# ATmega8535 device description
Architecture: AVR8; Family: megaAVR
Registers are 8-bit, access not given, no defined reset value unless marked. A register's access mark holds for its fields unless they carry their own. Offsets are from the block's base; [hi:lo] are bit positions.

## AC — Analog Comparator
Instances: AC 0x00
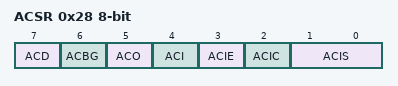
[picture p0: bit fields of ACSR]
0x28 ACSR — Analog Comparator Control And Status Register
  [7] ACD — Analog Comparator Disable
  [6] ACBG — Analog Comparator Bandgap Select
  [5] ACO — Analog Compare Output
  [4] ACI — Analog Comparator Interrupt Flag
  [3] ACIE — Analog Comparator Interrupt Enable
  [2] ACIC — Analog Comparator Input Capture Enable
  [1:0] ACIS — Analog Comparator Interrupt Mode Select bits
    0=Interrupt on Toggle; 2=Interrupt on Falling Edge; 3=Interrupt on Rising Edge

## TWI — Two Wire Serial Interface
Instances: TWI 0x00
0x20 TWBR — TWI Bit Rate register
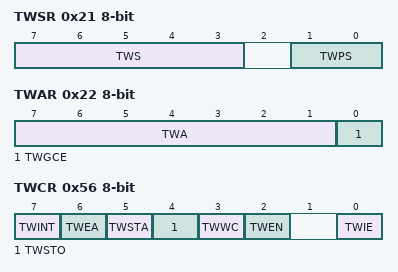
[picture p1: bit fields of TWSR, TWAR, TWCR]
0x21 TWSR — TWI Status Register
  [7:3] TWS (bit 3 of the value upward) — TWI Status
  [1:0] TWPS — TWI Prescaler
    0=1; 1=4; 2=16; 3=64
0x22 TWAR — TWI (Slave) Address register
  [7:1] TWA — TWI (Slave) Address register Bits
  [0] TWGCE — TWI General Call Recognition Enable Bit
0x23 TWDR — TWI Data register
0x56 TWCR — TWI Control Register
  [7] TWINT — TWI Interrupt Flag
  [6] TWEA — TWI Enable Acknowledge Bit
  [5] TWSTA — TWI Start Condition Bit
  [4] TWSTO — TWI Stop Condition Bit
  [3] TWWC — TWI Write Collition Flag
  [2] TWEN — TWI Enable Bit
  [0] TWIE — TWI Interrupt Enable

## USART
Instances: USART 0x00
0x29 UBRRL — USART Baud Rate Register Low Byte
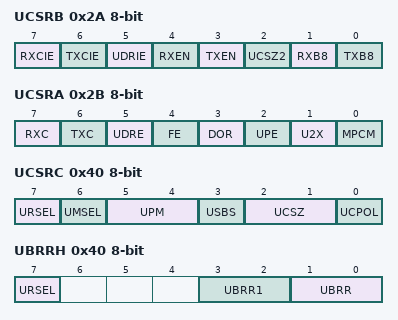
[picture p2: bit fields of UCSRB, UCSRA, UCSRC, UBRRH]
0x2A UCSRB — USART Control and Status Register B
  [7] RXCIE — RX Complete Interrupt Enable
  [6] TXCIE — TX Complete Interrupt Enable
  [5] UDRIE — USART Data register Empty Interrupt Enable
  [4] RXEN — Receiver Enable
  [3] TXEN — Transmitter Enable
  [2] UCSZ2 — Character Size Bit 2
  [1] RXB8 — Receive Data Bit 8
  [0] TXB8 — Transmit Data Bit 8
0x2B UCSRA — USART Control and Status Register A
  [7] RXC — USART Receive Complete
  [6] TXC — USART Transmitt Complete
  [5] UDRE — USART Data Register Empty
  [4] FE — Framing Error
  [3] DOR — Data overRun
  [2] UPE — Parity Error
  [1] U2X — Double the USART transmission speed
  [0] MPCM — Multi-processor Communication Mode
0x2C UDR — USART I/O Data Register
0x40 UCSRC — USART Control and Status Register C
  [7] URSEL — Register Select
  [6] UMSEL — USART Mode Select
    0=Asynchronous Operation; 1=Synchronous Operation
  [5:4] UPM — Parity Mode Bits
    0=Disabled; 2=Enabled, Even Parity; 3=Enabled, Odd Parity
  [3] USBS — Stop Bit Select
    0=1-bit; 1=2-bit
  [2:1] UCSZ — Character Size Bits
  [0] UCPOL — Clock Polarity
0x40 UBRRH — USART Baud Rate Register High Byte
  [7] URSEL — Register Select
  [3:2] UBRR1 — USART Baud Rate Register bit 11
  [1:0] UBRR (bit 8 of the value upward) — USART Baud Rate Register bits

## PORTA — I/O Port
Instances: PORTA 0x00
0x39 PINA — Port A Input Pins
0x3A DDRA — Port A Data Direction Register
0x3B PORTA — Port A Data Register

## PORTB — I/O Port
Instances: PORTB 0x00
0x36 PINB — Port B Input Pins
0x37 DDRB — Port B Data Direction Register
0x38 PORTB — Port B Data Register

## PORTC — I/O Port
Instances: PORTC 0x00
0x33 PINC — Port C Input Pins
0x34 DDRC — Port C Data Direction Register
0x35 PORTC — Port C Data Register

## PORTD — I/O Port
Instances: PORTD 0x00
0x30 PIND — Port D Input Pins
0x31 DDRD — Port D Data Direction Register
0x32 PORTD — Port D Data Register

## SPI — Serial Peripheral Interface
Instances: SPI 0x00
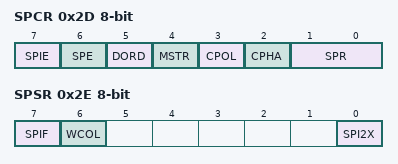
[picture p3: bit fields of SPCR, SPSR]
0x2D SPCR — SPI Control Register
  [7] SPIE — SPI Interrupt Enable
  [6] SPE — SPI Enable
  [5] DORD — Data Order
  [4] MSTR — Master/Slave Select
  [3] CPOL — Clock polarity
  [2] CPHA — Clock Phase
  [1:0] SPR — SPI Clock Rate Selects
    0=fosc/4; 1=fosc/16; 2=fosc/64; 3=fosc/128; 4=fosc/2; 5=fosc/8; 6=fosc/32; 7=fosc/64
0x2E SPSR — SPI Status Register
  [7] SPIF — SPI Interrupt Flag
  [6] WCOL — Write Collision Flag
  [0] SPI2X — Double SPI Speed Bit
0x2F SPDR — SPI Data Register
